# CH32X315 register map
Vendor: WCH Ltd.; File version: 1.1
Registers are 32-bit, read-write, reset 0x0 unless marked. A register's access mark holds for its fields unless they carry their own. Offsets are from the block's base; [hi:lo] are bit positions; {n}, {i} and the like mark numbered series.

## TIM2 — General purpose timer
Base 0x40000000
Same registers: TIM3 0x40000400
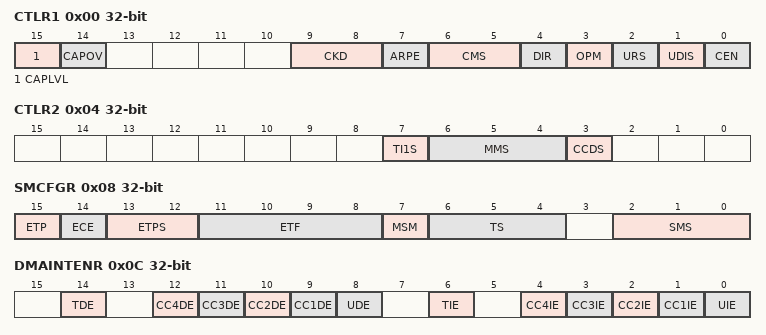
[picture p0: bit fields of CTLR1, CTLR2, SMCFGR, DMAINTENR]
0x00 CTLR1 — control register 1
  [15] CAPLVL — Directive function enable
  [14] CAPOV — Capture the value mode configuration
  [9:8] CKD — Clock division
  [7] ARPE — Auto-reload preload enable
  [6:5] CMS — Center-aligned mode selection
  [4] DIR — Direction
  [3] OPM — One-pulse mode
  [2] URS — Update request source
  [1] UDIS — Update disable
  [0] CEN — Counter enable
0x04 CTLR2 — control register 2
  [7] TI1S — TI1 selection
  [6:4] MMS — Master mode selection
  [3] CCDS — Capture/compare DMA selection
0x08 SMCFGR — slave mode control register
  [15] ETP — External trigger polarity
  [14] ECE — External clock enable
  [13:12] ETPS — External trigger prescaler
  [11:8] ETF — External trigger filter
  [7] MSM — Master/Slave mode
  [6:4] TS — Trigger selection
  [2:0] SMS — Slave mode selection
0x0C DMAINTENR — DMA/Interrupt enable register
  [14] TDE — Trigger DMA request enable
  [n+8] CC{n}DE (n=1..4) — Capture/Compare {n} DMA request enable
  [8] UDE — Update DMA request enable
  [6] TIE — Trigger interrupt enable
  [n] CC{n}IE (n=1..4) — Capture/Compare {n} interrupt enable
  [0] UIE — Update interrupt enable
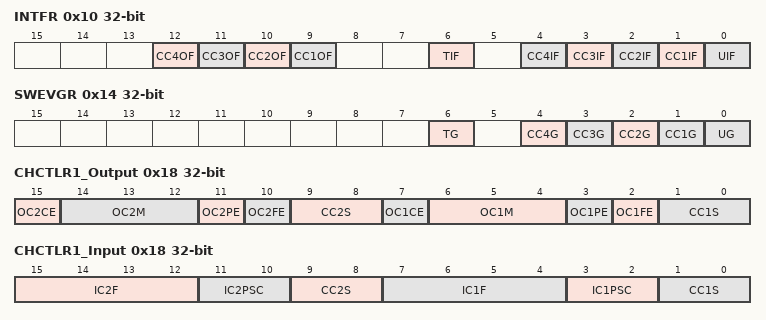
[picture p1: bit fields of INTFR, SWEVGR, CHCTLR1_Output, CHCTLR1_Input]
0x10 INTFR — status register
  [12] CC4OF — Capture/Compare 4 overcapture flag
  [11] CC3OF — Capture/Compare 3 overcapture flag
  [10] CC2OF — Capture/compare 2 overcapture flag
  [9] CC1OF — Capture/Compare 1 overcapture flag
  [6] TIF — Trigger interrupt flag
  [4] CC4IF — Capture/Compare 4 interrupt flag
  [3] CC3IF — Capture/Compare 3 interrupt flag
  [2] CC2IF — Capture/Compare 2 interrupt flag
  [1] CC1IF — Capture/compare 1 interrupt flag
  [0] UIF — Update interrupt flag
0x14 SWEVGR wo — event generation register
  [6] TG — Trigger generation
  [n] CC{n}G (n=1..4) — Capture/compare {n} generation
  [0] UG — Update generation
0x18 CHCTLR1_Output — capture/compare mode register 1 (output mode)
  [15] OC2CE — Output compare 2 clear enable
  [14:12] OC2M — Output compare 2 mode
  [11] OC2PE — Output compare 2 preload enable
  [10] OC2FE — Output compare 2 fast enable
  [9:8] CC2S — Capture/Compare 2 selection
  [7] OC1CE — Output compare 1 clear enable
  [6:4] OC1M — Output compare 1 mode
  [3] OC1PE — Output compare 1 preload enable
  [2] OC1FE — Output compare 1 fast enable
  [1:0] CC1S — Capture/Compare 1 selection
0x18 CHCTLR1_Input (alternate view of CHCTLR1_Output) — capture/compare mode register 1 (input mode)
  [15:12] IC2F — Input capture 2 filter
  [11:10] IC2PSC — Input capture 2 prescaler
  [9:8] CC2S — Capture/compare 2 selection
  [7:4] IC1F — Input capture 1 filter
  [3:2] IC1PSC — Input capture 1 prescaler
  [1:0] CC1S — Capture/Compare 1 selection
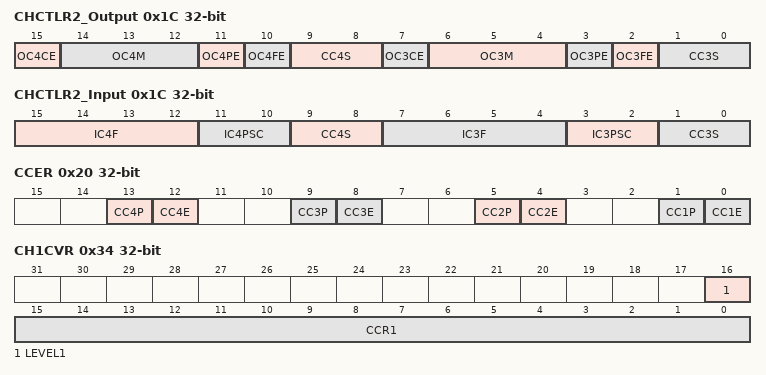
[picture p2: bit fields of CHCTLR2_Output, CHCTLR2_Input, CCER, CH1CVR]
0x1C CHCTLR2_Output — capture/compare mode register 2 (output mode)
  [15] OC4CE — Output compare 4 clear enable
  [14:12] OC4M — Output compare 4 mode
  [11] OC4PE — Output compare 4 preload enable
  [10] OC4FE — Output compare 4 fast enable
  [9:8] CC4S — Capture/Compare 4 selection
  [7] OC3CE — Output compare 3 clear enable
  [6:4] OC3M — Output compare 3 mode
  [3] OC3PE — Output compare 3 preload enable
  [2] OC3FE — Output compare 3 fast enable
  [1:0] CC3S — Capture/Compare 3 selection
0x1C CHCTLR2_Input (alternate view of CHCTLR2_Output) — capture/compare mode register 2 (input mode)
  [15:12] IC4F — Input capture 4 filter
  [11:10] IC4PSC — Input capture 4 prescaler
  [9:8] CC4S — Capture/Compare 4 selection
  [7:4] IC3F — Input capture 3 filter
  [3:2] IC3PSC — Input capture 3 prescaler
  [1:0] CC3S — Capture/Compare 3 selection
0x20 CCER — capture/compare enable register
  [13] CC4P — Capture/Compare 3 output Polarity
  [4n-4] CC{n}E (n=1..4) — Capture/Compare {n} output enable
  [9] CC3P — Capture/Compare 3 output Polarity
  [5] CC2P — Capture/Compare 2 output Polarity
  [1] CC1P — Capture/Compare 1 output Polarity
0x24 CNT — counter
  [15:0] CNT — counter value
0x28 PSC — prescaler
  [15:0] PSC — Prescaler value
0x2C ATRLR reset 0xFFFF — auto-reload register
  [15:0] ARR — Auto-reload value
0x34 CH1CVR — capture/compare register 1
  [16] LEVEL1 — Level indicating bit
  [15:0] CCR1 — Capture/Compare 1 value
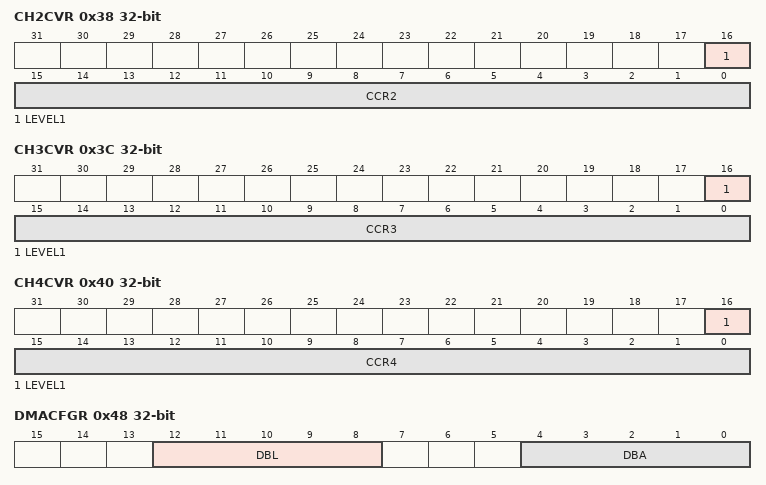
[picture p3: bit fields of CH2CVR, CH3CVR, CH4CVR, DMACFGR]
0x38 CH2CVR — capture/compare register 2
  [16] LEVEL1 — Level indicating bit
  [15:0] CCR2 — Capture/Compare 2 value
0x3C CH3CVR — capture/compare register 3
  [16] LEVEL1 — Level indicating bit
  [15:0] CCR3 — Capture/Compare value
0x40 CH4CVR — capture/compare register 4
  [16] LEVEL1 — Level indicating bit
  [15:0] CCR4 — Capture/Compare value
0x48 DMACFGR — DMA control register
  [12:8] DBL — DMA burst length
  [4:0] DBA — DMA base address
0x4C DMAADR — DMA address for full transfer
  [15:0] DMAADR — DMA register for burst accesses

## TIM4 — General purpose timer
Base 0x40000800
Registers as TIM2; these are added or differ:
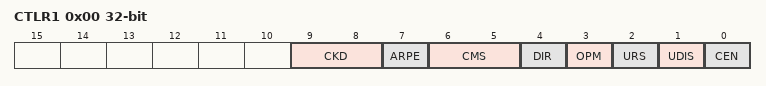
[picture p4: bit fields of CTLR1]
0x00 CTLR1 — control register 1
  [9:8] CKD — Clock division
  [7] ARPE — Auto-reload preload enable
  [6:5] CMS — Center-aligned mode selection
  [4] DIR — Direction
  [3] OPM — One-pulse mode
  [2] URS — Update request source
  [1] UDIS — Update disable
  [0] CEN — Counter enable
0x24 CNT — counter
  [31:0] CNT — counter value
0x2C ATRLR reset 0xFFFFFFFF — auto-reload register
  [31:0] ARR — Auto-reload value
0x34 CH1CVR — capture/compare register 1
  [31:0] CCR1 — Capture/Compare 1 value
0x38 CH2CVR — capture/compare register 2
  [31:0] CCR2 — Capture/Compare 2 value
0x3C CH3CVR — capture/compare register 3
  [31:0] CCR3 — Capture/Compare value
0x40 CH4CVR — capture/compare register 4
  [31:0] CCR4 — Capture/Compare value
0x4C DMAADR — DMA address for full transfer
  [31:0] DMAADR — DMA register for burst accesses
